# psoc6_01 register map
Vendor: Infineon Technologies; Series: PSOC6_01; File version: 1.0
CPU: CM4 r0p1, little endian, MPU, FPU, VTOR, 3 interrupt priority bits
Registers are 32-bit, read-write, reset 0x0 unless marked. A register's access mark holds for its fields unless they carry their own. Offsets are from the block's base; [hi:lo] are bit positions; {n}, {i} and the like mark numbered series; <NAME> marks a mode.

## CRYPTO — Cryptography component
Base 0x40110000
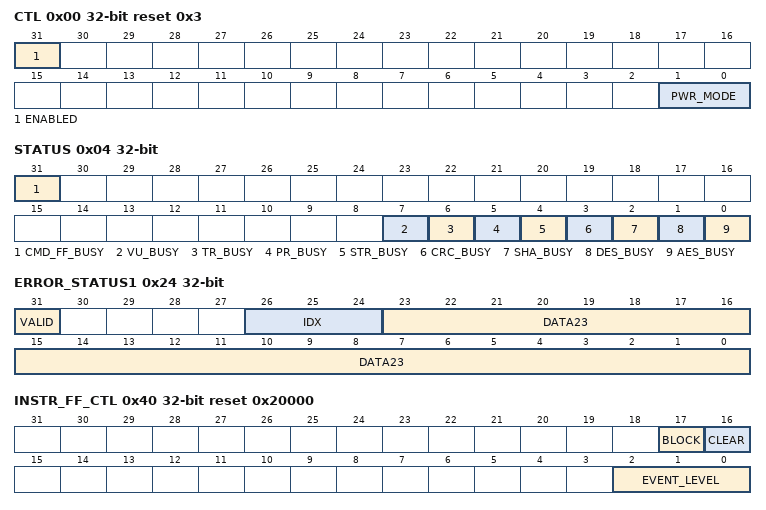
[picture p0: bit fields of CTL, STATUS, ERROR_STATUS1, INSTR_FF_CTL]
0x00 CTL reset 0x3 — Control
  [31] ENABLED — IP enable: '0': Disabled. All non-retention registers (command and status registers) are reset to their default value when the IP is disabled. All retention registers retain their value when the IP is disabled. '1': Enabled.
    0=DISABLED (N/A); 1=ENABLED (N/A)
  [1:0] PWR_MODE — Set power mode for memory buffer SRAM.
    0=OFF (See CM4_PWR_CTL); 1=RSVD (undefined); 2=RETAINED (See CM4_PWR_CTL); 3=ENABLED (See CM4_PWR_CTL)
0x04 STATUS ro
  [31] CMD_FF_BUSY — Reflects the state of the command FIFO (copy of CMD_FF_STATUS.BUSY): '0': No instruction pending. '1': Instruction pending.
  [7] VU_BUSY — Reflects the state of the vector unit component.
  [6] TR_BUSY — Reflects the state of the TR component.
  [5] PR_BUSY — Reflects the state of the PR component.
  [4] STR_BUSY — Reflects the state of the CRC component.
  [3] CRC_BUSY — Reflects the state of the CRC component.
  [2] SHA_BUSY — Reflects the state of the SHA component.
  [1] DES_BUSY — Reflects the state of the DES component.
  [0] AES_BUSY — Reflects the state of the AES component: '0': Component is not busy. '1': Component is busy performing an instruction. When the component is busy, it is NOT possible to start another operation. However, it is possible to access the instruction FIFO or memory buffer (to prepare for another operation).
0x08 RAM_PWRUP_DELAY reset 0x96 — Power up delay used for SRAM power domain
  [9:0] PWRUP_DELAY — Number clock cycles delay needed after power domain power up
0x20 ERROR_STATUS0 ro reset not defined
  [31:0] DATA32 — Captures error description information. For INSTR_OPC_ERROR: - Violating instruction. For INSTR_CC_ERROR: - Violating instruction. For BUS_ERROR: - Violating transfer address.
0x24 ERROR_STATUS1 (reset mask 0x87000000)
  [31] VALID — Specifies if ERROR_STATUS0 and ERROR_STATUS1 capture valid error information.
  [26:24] IDX — Error source: '0': INSTR_OPC_ERROR, instruction decoder error. '1': INSTR_CC_ERROR, instruction condition code error. '2': BUS_ERROR, Bus master interface AHB-Lite bus error. '3': TR_AP_DETECT_ERROR. '4': TR_RC_DETECT_ERROR. '5'-'7': Undefined.
  [23:0] DATA23 ro — Captures error description information. For BUS_ERROR: - Violating transfer, read attribute (DATA23[0]). - Violating transfer, size attribute (DATA23[5:4]). '0': 8-bit transfer, '1': 16 bits transfer, '2': 32-bit transfer. For INSTR_CC_ERROR:
0x40 INSTR_FF_CTL reset 0x20000 — Instruction FIFO control
  [17] BLOCK — This field specifies the behavior when an instruction is written to a full FIFO (INSTR_FIFO_WR MMIO register): '0': The write is ignored/dropped and the INTR.INSTR_FF_OVERFLOW interrupt cause is set to '1'. '1': The write is blocked, resulting in AHB-Lite wait states and the INTR.INSTR_FF_OVERFLOW interrupt cause is set to '1' (this cause may be masked out). The instruction is written to the FIFO as soon as a FIFO entry becomes available. The maximum time is roughly the time of the execution of the slowest/longest instruction. Note that this setting may 'lock up' the CPU. When the CPU is 'locked up' it can not respond to interrupts. As a result, the interrupt latency is increased.
  [16] CLEAR — When '1', the instruction FIFO is cleared/invalidated. Invalidation will last for as long as this field is '1'. If a quick clear/invalidation is required, the field should be set to '1' and be followed by a set to '0'. If a clear/invalidation is required for an extended time period, the field should be set to '1' during the complete time period. HW sets this field to '1' on when an error INTR cause is activated.
  [2:0] EVENT_LEVEL — Event level. When the number of entries in the instruction FIFO is less than the amount of this field, an event is generated: - 'event' = INSTR_FF_STATUS.USED < EVENT_LEVEL.
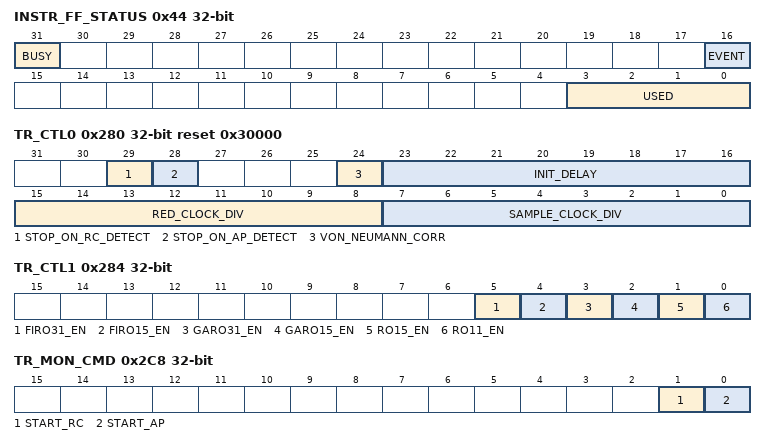
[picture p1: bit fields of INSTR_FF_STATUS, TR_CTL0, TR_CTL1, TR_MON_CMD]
0x44 INSTR_FF_STATUS ro — Instruction FIFO status
  [31] BUSY — Reflects the state of the instruction FIFO: '0': No instruction pending (USED is '0'). '1': Instruction pending.
  [16] EVENT — Instruction FIFO event.
  [3:0] USED — Number of instructions in the instruction FIFO. The value of this field ranges from 0 to 8.
0x48 INSTR_FF_WR wo — Instruction FIFO write
  [31:0] DATA32 — Instruction or instruction operand data that is written to the instruction FIFO.
{0x80+4i} RF_DATA[{i}] (i=0..15) ro — Register-file
  [31:0] DATA32 — Register-file data. For the vector unit component, a register-file register has the following layout: DATA[29:16]: data DATA[11:0]: bit size (minus 1)
0x100 AES_CTL — AES control
  [1:0] KEY_SIZE — AES key size: '0': 128-bit key, 10 rounds AES (inverse) cipher operation. SRC_CTL0 specifies the location of a 16 Byte key. '1': 192-bit key, 12 rounds AES (inverse) cipher operation. SRC_CTL0 specifies the location of a 24 Byte key. '2': 256-bit key, 14 rounds AES (inverse) cipher operation. SRC_CTL0 specifies the location of a 32 Byte key. '3': Undefined
    0=AES128 (N/A); 1=AES192 (N/A); 2=AES256 (N/A)
0x180 STR_RESULT ro reset not defined — String result
  [0] MEMCMP — Result of a STR_MEMCMP operation: '0': source 0 equals source 1. '1': source 0 does NOT equal source 1.
0x200 PR_LFSR_CTL0 reset 0xD8959BC9 — Pseudo random LFSR control 0
  [31:0] LFSR32 — State of a 32-bit Linear Feedback Shift Registers (LFSR) that is used to generate a pseudo random bit sequence. This register needs to be initialized by SW. The initialization value should be different from '0'. The three PR_LFSR_CTL registers represents the state of a 32-bit, 31-bit and 29-bit LFSR. Individually, these LFSRs generate a pseudo random bit sequence that repeats itself after (2^32)-1, (2^31)-1 and (2^29)-1 bits. The numbers (2^32)-1, (2^31)-1 and (2^29)-1 are relatively prime (their greatest common denominator is '1'). The three bit sequence are combined (XOR'd) into a single bitstream to create a pseudo random bit sequence that repeats itself after ((2^32)-1) * ((2^31)-1) * ((2*29)-1) bits. The following polynomials are used: - 32-bit irreducible polynomial: x^32+x^30+x^26+x^25+1. - 31-bit irreducible polynomial: x^31+x^28+1. - 29-bit irreducible polynomial: x^29+x^27+1.
0x204 PR_LFSR_CTL1 reset 0x2BB911F8 — Pseudo random LFSR control 1
  [30:0] LFSR31 — State of a 31-bit Linear Feedback Shift Registers (LFSR) that is used to generate a pseudo random bit sequence. See PR_LFSR_CTL0.
0x208 PR_LFSR_CTL2 reset 0x60C31B7 — Pseudo random LFSR control 2
  [28:0] LFSR29 — State of a 29-bit Linear Feedback Shift Registers (LFSR) that is used to generate a pseudo random bit sequence. See PR_LFSR_CTL0.
0x210 PR_RESULT — Pseudo random result
  [31:0] DATA32 — Result of a pseudo random number generation operation. The resulting value DATA is in the range [0, MAX], with MAX specified by rsrc0. HW generates the number in this field. Note that SW can write this field. This functionality can be used prevent information leakage.
0x280 TR_CTL0 reset 0x30000 — True random control 0
  [29] STOP_ON_RC_DETECT — Specifies if TRNG functionality is stopped on a repetition count test detection (when HW sets INTR.TR_RC_DETECT to '1'): '0': Functionality is NOT stopped. '1': Functionality is stopped (TR_CTL1 fields are set to '0' by HW).
  [28] STOP_ON_AP_DETECT — Specifies if TRNG functionality is stopped on an adaptive proportion test detection (when HW sets INTR.TR_AP_DETECT to '1'): '0': Functionality is NOT stopped. '1': Functionality is stopped (TR_CTL1 fields are set to '0' by HW).
  [24] VON_NEUMANN_CORR — Specifies if the 'von Neumann corrector' is disabled or enabled: '0': disabled. '1': enabled. The 'von Neumann corrector' post-processes the reduced bits to remove a '0' or '1' bias. The corrector operates on reduced bit pairs ('oldest bit, newest bit'): '00': no bit is produced. '01': '0' bit is produced (oldest bit). '10': '1' bit is produced (oldest bit). '11': no bit is produced. Note that the corrector produces bits at a random pace and at a frequency that is 1/4 of the reduced bit frequency (reduced bits are processed in pairs, and half of the pairs do NOT produce a bit).
  [23:16] INIT_DELAY — Specifies an initialization delay: number of removed/dropped samples before reduced bits are generated. This field should be programmed in the range [1, 255]. After starting the oscillators, at least the first 2 samples should be removed/dropped to clear the state of internal synchronizers. In addition, it is advised to drop at least the second 2 samples from the oscillators (to circumvent the semi-predictable oscillator startup behavior). This result in the default field value of '3'. Field encoding is as follows: '0': 1 sample is dropped. '1': 2 samples are dropped. ... '255': 256 samples are dropped. The TR_INITIALIZED interrupt cause is set to '1', when the initialization delay is passed.
  [15:8] RED_CLOCK_DIV — Specifies the clock divider that is used to produce reduced bits. '0': 1 reduced bit is produced for each sample. '1': 1 reduced bit is produced for each 2 samples. ... '255': 1 reduced bit is produced for each 256 samples. The reduced bits are considered random bits and shifted into TR_RESULT0.DATA32.
  [7:0] SAMPLE_CLOCK_DIV — Specifies the clock divider that is used to sample oscillator data. This clock divider is wrt. 'clk_sys'. '0': sample clock is 'clk_sys'. '1': sample clock is 'clk_sys'/2. ... '255': sample clock is 'clk_sys'/256.
0x284 TR_CTL1 — True random control 1
  [5] FIRO31_EN — FW sets this field to '1' to enable the programmable Fibonacci ring oscillator with up to 31 inverters. The TR_FIRO_CTL register specifies the programmable polynomial.
  [4] FIRO15_EN — FW sets this field to '1' to enable the fixed Fibonacci ring oscillator with 15 inverters.
  [3] GARO31_EN — FW sets this field to '1' to enable the programmable Galois ring oscillator with up to 31 inverters. The TR_GARO_CTL register specifies the programmable polynomial.
  [2] GARO15_EN — FW sets this field to '1' to enable the fixed Galois ring oscillator with 15 inverters.
  [1] RO15_EN — FW sets this field to '1' to enable the ring oscillator with 15 inverters.
  [0] RO11_EN — FW sets this field to '1' to enable the ring oscillator with 11 inverters.
0x288 TR_RESULT — True random result
  [31:0] DATA32 — Generated true random number. HW generates the number in the least significant bit positions of this field. The TR_DATA_AVAILABLE interrupt cause is activated when the number is generated. Note that SW can write this field. This functionality can be used prevent information leakage.
0x2A0 TR_GARO_CTL — True random GARO control
  [30:0] POLYNOMIAL31 — Polynomial for programmable Galois ring oscillator. The polynomial is represented WITHOUT the high order bit (this bit is always assumed '1'). The polynomial should be aligned such that the more significant bits (bit 30 and down) contain the polynomial and the less significant bits (bit 0 and up) contain padding '0's.
0x2A4 TR_FIRO_CTL — True random FIRO control
  [30:0] POLYNOMIAL31 — Polynomial for programmable Fibonacci ring oscillator. The polynomial is represented WITHOUT the high order bit (this bit is always assumed '1'). The polynomial should be aligned such that the more significant bits (bit 30 and down) contain the polynomial and the less significant bits (bit 0 and up) contain padding '0's.
0x2C0 TR_MON_CTL reset 0x2 — True random monitor control
  [1:0] BITSTREAM_SEL — Selection of the bitstream: '0': DAS bitstream. '1': RED bitstream. '2': TR bitstream. '3': Undefined.
0x2C8 TR_MON_CMD — True random monitor command
  [1] START_RC — Repetition count (RC) test enable: '0': Disabled. '1': Enabled. On a RC detection, HW sets this field to '0' and sets INTR.TR_RC_DETECT to '1.
  [0] START_AP — Adaptive proportion (AP) test enable: '0': Stopped. '1': Started. On a AP detection, HW sets this field to '0' and sets INTR.TR_AP_DETECT to '1.
0x2D0 TR_MON_RC_CTL reset 0xFF — True random monitor RC control
  [7:0] CUTOFF_COUNT8 — Cutoff count (legal range is [1, 255]): '0': Illegal. '1': 1 repetition. ... '255': 255 repetitions.
0x2D8 TR_MON_RC_STATUS0 ro — True random monitor RC status 0
  [0] BIT — Current active bit value: '0': '0'. '1': '1'. This field is only valid when TR_MON_RC_STATUS1.REP_COUNT is NOT equal to '0'.
0x2DC TR_MON_RC_STATUS1 ro — True random monitor RC status 1
  [7:0] REP_COUNT — Number of repetitions of the current active bit counter: '0': 0 repetitions. ... '255': 255 repetitions.
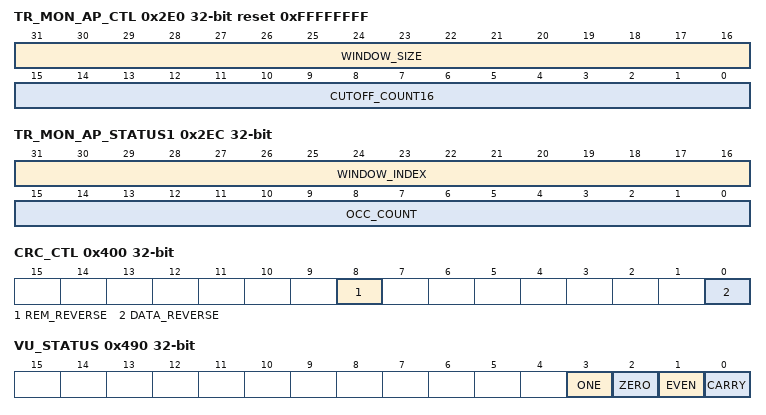
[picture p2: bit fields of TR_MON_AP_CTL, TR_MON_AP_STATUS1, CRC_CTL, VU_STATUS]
0x2E0 TR_MON_AP_CTL reset 0xFFFFFFFF — True random monitor AP control
  [31:16] WINDOW_SIZE — Window size (minus 1) : '0': 1 bit. ... '65535': 65536 bits.
  [15:0] CUTOFF_COUNT16 — Cutoff count (legal range is [1, 65535]). '0': Illegal. '1': 1 occurrence. ... '65535': 65535 occurrences.
0x2E8 TR_MON_AP_STATUS0 ro — True random monitor AP status 0
  [0] BIT — Current active bit value: '0': '0'. '1': '1'. This field is only valid when TR_MON_AP_STATUS1.OCC_COUNT is NOT equal to '0'.
0x2EC TR_MON_AP_STATUS1 ro — True random monitor AP status 1
  [31:16] WINDOW_INDEX — Counter to keep track of the current index in the window (counts from '0' to TR_MON_AP_CTL.WINDOW_SIZE).
  [15:0] OCC_COUNT — Number of occurrences of the current active bit counter: '0': 0 occurrences ... '65535': 65535 occurrences
0x300 SHA_CTL — SHA control
  [2:0] MODE — SHA mode: '0': SHA1. The message is 16 32 bits words: 64 Bytes. The hash is 5 32-bit words: 20 Bytes. There are 80 32-bit message schedule round constants: 320 Bytes. '1': SHA224, SHA256. The message is 16 32-bit words: 64 Bytes. The hash is 8 32-bit words: 32 Bytes. There are 64 32-bit message schedule round constants: 256 Bytes. The difference between SHA224 and SHA256 is entirely in software (differences in initialization hash and message digest size). '2': SHA512/224, SHA512/256, SHA384, SHA512. The message is 8 64-bit words: 64 Bytes. The hash is 8 64-bit words: 64 Bytes. There are 80 64-bit message schedule round constants: 640 Bytes. The difference between SHA512/224, SHA512/256, SHA384 and SHA512 is entirely in software (differences in initialization hash and message digest size). '3'-'7': Undefined.
    0=SHA1 (N/A); 1=SHA256 (N/A); 2=SHA512 (N/A)
0x400 CRC_CTL — CRC control
  [8] REM_REVERSE — Specifies whether the remainder is bit reversed (reversal is performed after XORing): '0': No. '1': Yes.
  [0] DATA_REVERSE — Specifies the bit order in which a data Byte is processed (reversal is performed after XORing): '0': Most significant bit (bit 1) first. '1': Least significant bit (bit 0) first.
0x410 CRC_DATA_CTL — CRC data control
  [7:0] DATA_XOR — Specifies a byte mask with which each data byte is XOR'd. The XOR is performed before data reversal.
0x420 CRC_POL_CTL — CRC polynomial control
  [31:0] POLYNOMIAL — CRC polynomial. The polynomial is represented WITHOUT the high order bit (this bit is always assumed '1'). The polynomial should be aligned/shifted such that the more significant bits (bit 31 and down) contain the polynomial and the less significant bits (bit 0 and up) contain padding '0's. Some frequently used polynomials: - CRC32: POLYNOMIAL is 0x04c11db7 (x^32 + x^26 + x^23 + x^22 + x^16 + x^12 + x^11 + x^10 + x^8 + x^7 + x^5 + x^4 + x^2 + x + 1). - CRC16: POLYNOMIAL is 0x80050000 (x^16 + x^15 + x^2 + 1, shifted by 16 bit positions). - CRC16 CCITT: POLYNOMIAL is 0x10210000 (x^16 + x^12 + x^5 + 1, shifted by 16 bit positions).
0x430 CRC_LFSR_CTL — CRC LFSR control
  [31:0] LFSR32 — State of a 32-bit Linear Feedback Shift Registers (LFSR) that is used to implement CRC. This register needs to be initialized by SW to provide the CRC seed value. The seed value should be aligned such that the more significant bits (bit 31 and down) contain the seed value and the less significant bits (bit 0 and up) contain padding '0's. Note that SW can write this field. This functionality can be used prevent information leakage (through either CRC_LFSR_CTL or CRC_REM_RESULT) from the privileged domain to the user domain.
0x440 CRC_REM_CTL — CRC remainder control
  [31:0] REM_XOR — Specifies a mask with which the CRC_LFSR_CTL.LFSR32 register is XOR'd to produce a remainder. The XOR is performed before remainder reversal.
0x448 CRC_REM_RESULT ro — CRC remainder result
  [31:0] REM — Remainder value. The alignment of the remainder depends on CRC_REM_CTL0.REM_REVERSE: '0': the more significant bits (bit 31 and down) contain the remainder. '1': the less significant bits (bit 0 and up) contain the remainder. Note: This field is combinatorially derived from CRC_LFSR_CTL.LFSR32, CRC_REM_CTL0.REM_REVERSE and CRC_REM_CTL1.REM_XOR.
0x480 VU_CTL0 — Vector unit control 0
  [0] ALWAYS_EXECUTE — Specifies if a conditional instruction is executed or not, when its condition code evaluates to false/'0'. '0': The instruction is NOT executed. As a result, the instruction may be handled faster than when it is executed. '1': The instruction is executed, but the execution result (including status field information) is not reflected in the IP. The instruction is handled just as fast as when it is executed. Note: a conditional instruction with a condition code that evaluates to false/'0' does not affect the architectural state: VU_STATUS fields, memory or register-file data. Note: Always execution is useful to prevent/complicate differential timing and differential power attacks.
0x484 VU_CTL1 — Vector unit control 1
  [31:14] ADDR — Specifies base address of vector unit operands in memory. The register-file registers provide offsets wrt. this base address. The base address is a multiple of 16 KB. The register-file registers provide 12-bit word address offsets in this 16 KB. Together, they provide access to a 16 KB memory region for vector unit instructions: ADDR[31:14] = VU_CTL1.ADDR[31:14] ADDR[13:2] = register-file register offset The base address is either the IP's internal memory buffer (memory capacity is the internal memory buffer capacity) or a location in system memory (memory capacity is 16 KB). For best performance, the IP's memory buffer should be used and VU_CTL1.ADDR should be programmed to MEM_BUFF. If VU_CTL1.ADDR is set to MEM_BUFF and the memory buffer capacity is less than 16 KB, memory accesses beyond the memory buffer capacity access a memory hole (reads return '0' and writes are ignored). E.g., if the memory buffer is 8 KB, accesses with ADDR[13] set to '1', access a memory hole. If the IP's memory buffer capacity is not large enough to support the vector unit operands, VU_CTL1.ADDR can be set to a 16 KB aligned location in system memory.
0x490 VU_STATUS ro — Vector unit status
  [3] ONE — STATUS ONE field.
  [2] ZERO — STATUS ZERO field.
  [1] EVEN — STATUS EVEN field.
  [0] CARRY — STATUS CARRY field.
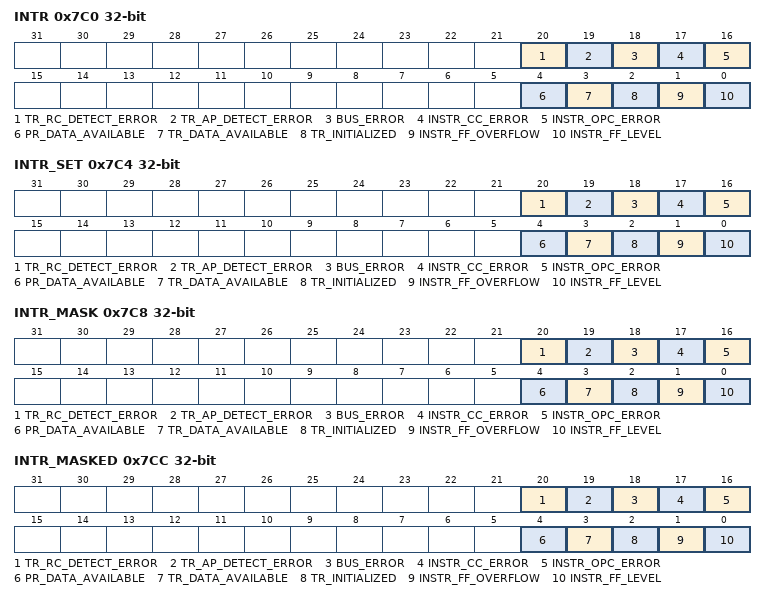
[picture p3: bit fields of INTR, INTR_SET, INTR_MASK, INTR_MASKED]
0x7C0 INTR — Interrupt register
  [20] TR_RC_DETECT_ERROR — This interrupt cause is activated (HW sets the field to '1') when the true random number generator monitor adaptive proportion test detects a disproportionate occurrence of a specific bit value.
  [19] TR_AP_DETECT_ERROR — This interrupt cause is activated (HW sets the field to '1') when the true random number generator monitor adaptive proportion test detects a repetition of a specific bit value.
  [18] BUS_ERROR — This interrupt cause is activated (HW sets the field to '1') when a AHB-Lite bus error is observed on the AHB-Lite master interface.
  [17] INSTR_CC_ERROR — This interrupt cause is activated (HW sets the field to '1') when the instruction decoder encounters an instruction with a non-defined condition code. This error is only generated for VU instructions.
  [16] INSTR_OPC_ERROR — This interrupt cause is activated (HW sets the field to '1') when the instruction decoder encounters an instruction with a non-defined operation code (opcode).
  [4] PR_DATA_AVAILABLE — This interrupt cause is activated (HW sets the field to '1') when the pseudo random number generator has generated a data value.
  [3] TR_DATA_AVAILABLE — This interrupt cause is activated (HW sets the field to '1') when the true random number generator has generated a data value of the specified bit size.
  [2] TR_INITIALIZED — This interrupt cause is activated (HW sets the field to '1') when the true random number generator is initialized.
  [1] INSTR_FF_OVERFLOW — This interrupt cause is activated (HW sets the field to '1') when the instruction FIFO overflows (an attempt is made to write to a full FIFO).
  [0] INSTR_FF_LEVEL — This interrupt cause is activated (HW sets the field to '1') when the instruction FIFO event is activated.
0x7C4 INTR_SET — Interrupt set register
  [20] TR_RC_DETECT_ERROR — SW writes a '1' to this field to set the corresponding field in interrupt request register.
  [19] TR_AP_DETECT_ERROR — SW writes a '1' to this field to set the corresponding field in interrupt request register.
  [18] BUS_ERROR — SW writes a '1' to this field to set the corresponding field in interrupt request register.
  [17] INSTR_CC_ERROR — SW writes a '1' to this field to set the corresponding field in interrupt request register.
  [16] INSTR_OPC_ERROR — SW writes a '1' to this field to set the corresponding field in interrupt request register.
  [4] PR_DATA_AVAILABLE — SW writes a '1' to this field to set the corresponding field in interrupt request register.
  [3] TR_DATA_AVAILABLE — SW writes a '1' to this field to set the corresponding field in interrupt request register.
  [2] TR_INITIALIZED — SW writes a '1' to this field to set the corresponding field in interrupt request register.
  [1] INSTR_FF_OVERFLOW — SW writes a '1' to this field to set the corresponding field in interrupt request register.
  [0] INSTR_FF_LEVEL — SW writes a '1' to this field to set the corresponding field in interrupt request register.
0x7C8 INTR_MASK — Interrupt mask register
  [20] TR_RC_DETECT_ERROR — Mask bit for corresponding field in interrupt request register.
  [19] TR_AP_DETECT_ERROR — Mask bit for corresponding field in interrupt request register.
  [18] BUS_ERROR — Mask bit for corresponding field in interrupt request register.
  [17] INSTR_CC_ERROR — Mask bit for corresponding field in interrupt request register.
  [16] INSTR_OPC_ERROR — Mask bit for corresponding field in interrupt request register.
  [4] PR_DATA_AVAILABLE — Mask bit for corresponding field in interrupt request register.
  [3] TR_DATA_AVAILABLE — Mask bit for corresponding field in interrupt request register.
  [2] TR_INITIALIZED — Mask bit for corresponding field in interrupt request register.
  [1] INSTR_FF_OVERFLOW — Mask bit for corresponding field in interrupt request register.
  [0] INSTR_FF_LEVEL — Mask bit for corresponding field in interrupt request register.
0x7CC INTR_MASKED ro — Interrupt masked register
  [20] TR_RC_DETECT_ERROR — Logical and of corresponding request and mask bits.
  [19] TR_AP_DETECT_ERROR — Logical and of corresponding request and mask bits.
  [18] BUS_ERROR — Logical and of corresponding request and mask bits.
  [17] INSTR_CC_ERROR — Logical and of corresponding request and mask bits.
  [16] INSTR_OPC_ERROR — Logical and of corresponding request and mask bits.
  [4] PR_DATA_AVAILABLE — Logical and of corresponding request and mask bits.
  [3] TR_DATA_AVAILABLE — Logical and of corresponding request and mask bits.
  [2] TR_INITIALIZED — Logical and of corresponding request and mask bits.
  [1] INSTR_FF_OVERFLOW — Logical and of corresponding request and mask bits.
  [0] INSTR_FF_LEVEL — Logical and of corresponding request and mask bits.
